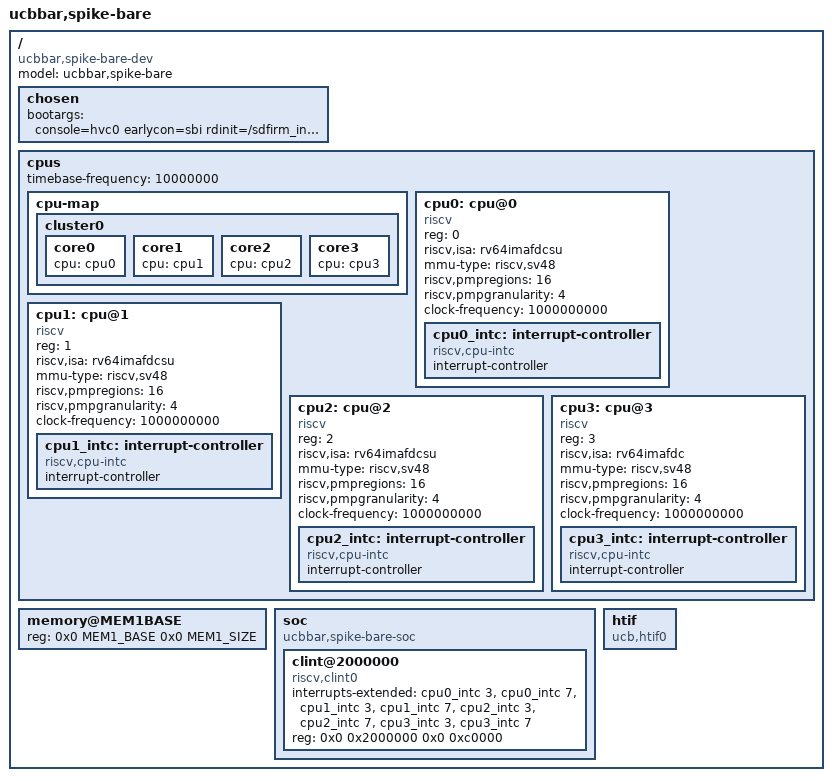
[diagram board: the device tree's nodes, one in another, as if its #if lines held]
#include <target/arch.h>

/dts-v1/;

/memreserve/ RAM_BASE 0x02000000;

/ {
	#address-cells = <2>;
	#size-cells = <2>;
	compatible = "ucbbar,spike-bare-dev";
	model = "ucbbar,spike-bare";
	chosen {
		bootargs = "console=hvc0 earlycon=sbi rdinit=/sdfirm_init";
	};
	cpus {
		#address-cells = <1>;
		#size-cells = <0>;
		timebase-frequency = <10000000>;

		cpu-map {
			cluster0 {
				core0 {
					cpu = <&cpu0>;
				};
#ifdef CONFIG_SMP
#if SPIKE_SMP_CPUS > 1
				core1 {
					cpu = <&cpu1>;
				};
#endif
#if SPIKE_SMP_CPUS > 2
				core2 {
					cpu = <&cpu2>;
				};
#endif
#if SPIKE_SMP_CPUS > 3
				core3 {
					cpu = <&cpu3>;
				};
#endif
#endif
			};
		};

		cpu0: cpu@0 {
			device_type = "cpu";
			reg = <0>;
			status = "okay";
			compatible = "riscv";
			riscv,isa = "rv64imafdcsu";
			mmu-type = "riscv,sv48";
#ifdef CONFIG_RISCV_PMP
			riscv,pmpregions = <16>;
			riscv,pmpgranularity = <4>;
#endif
			clock-frequency = <1000000000>;
			cpu0_intc: interrupt-controller {
				#interrupt-cells = <1>;
				interrupt-controller;
				compatible = "riscv,cpu-intc";
			};
		};
#ifdef CONFIG_SMP
#if SPIKE_SMP_CPUS > 1
		cpu1: cpu@1 {
			device_type = "cpu";
			reg = <1>;
			status = "okay";
			compatible = "riscv";
			riscv,isa = "rv64imafdcsu";
			mmu-type = "riscv,sv48";
#ifdef CONFIG_RISCV_PMP
			riscv,pmpregions = <16>;
			riscv,pmpgranularity = <4>;
#endif
			clock-frequency = <1000000000>;
			cpu1_intc: interrupt-controller {
				#interrupt-cells = <1>;
				interrupt-controller;
				compatible = "riscv,cpu-intc";
			};
		};
#endif
#if SPIKE_SMP_CPUS > 2
		cpu2: cpu@2 {
			device_type = "cpu";
			reg = <2>;
			status = "okay";
			compatible = "riscv";
			riscv,isa = "rv64imafdcsu";
			mmu-type = "riscv,sv48";
#ifdef CONFIG_RISCV_PMP
			riscv,pmpregions = <16>;
			riscv,pmpgranularity = <4>;
#endif
			clock-frequency = <1000000000>;
			cpu2_intc: interrupt-controller {
				#interrupt-cells = <1>;
				interrupt-controller;
				compatible = "riscv,cpu-intc";
			};
		};
#endif
#if SPIKE_SMP_CPUS > 3
		cpu3: cpu@3 {
			device_type = "cpu";
			reg = <3>;
			status = "okay";
			compatible = "riscv";
			riscv,isa = "rv64imafdc";
			mmu-type = "riscv,sv48";
#ifdef CONFIG_RISCV_PMP
			riscv,pmpregions = <16>;
			riscv,pmpgranularity = <4>;
#endif
			clock-frequency = <1000000000>;
			cpu3_intc: interrupt-controller {
				#interrupt-cells = <1>;
				interrupt-controller;
				compatible = "riscv,cpu-intc";
			};
		};
#endif
#endif
	};
	memory@MEM1BASE {
		device_type = "memory";
		reg = <0x0 MEM1_BASE 0x0 MEM1_SIZE>;
	};
	soc {
		#address-cells = <2>;
		#size-cells = <2>;
		compatible = "ucbbar,spike-bare-soc", "simple-bus";
		clint@2000000 {
			compatible = "riscv,clint0";
			interrupts-extended = <
				&cpu0_intc 3 &cpu0_intc 7
#ifdef CONFIG_SMP
#if SPIKE_SMP_CPUS > 1
				&cpu1_intc 3 &cpu1_intc 7
#endif
#if SPIKE_SMP_CPUS > 2
				&cpu2_intc 3 &cpu2_intc 7
#endif
#if SPIKE_SMP_CPUS > 3
				&cpu3_intc 3 &cpu3_intc 7
#endif
#endif
			>;
			reg = <0x0 0x2000000 0x0 0xc0000>;
		};
	};
	htif {
		compatible = "ucb,htif0";
	};
};
